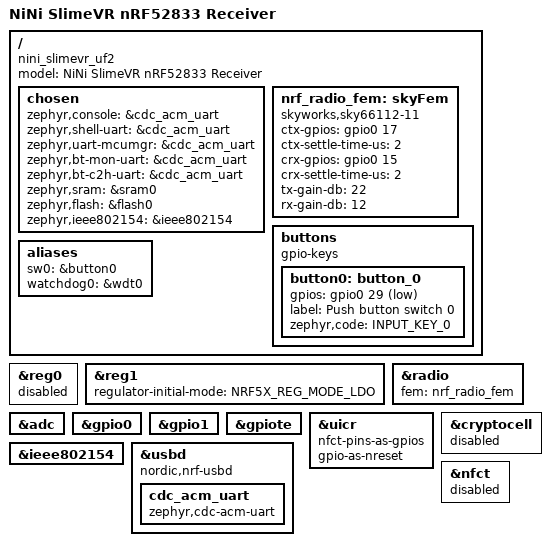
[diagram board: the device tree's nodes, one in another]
// Copyright (c) 2026
// SPDX-License-Identifier: Apache-2.0

/dts-v1/;
#include <nordic/nrf52833_qdaa.dtsi>
#include <zephyr/dt-bindings/input/input-event-codes.h>

/ {
	model = "NiNi SlimeVR nRF52833 Receiver";
	compatible = "nini_slimevr_uf2";

	chosen {
		zephyr,console = &cdc_acm_uart;
		zephyr,shell-uart = &cdc_acm_uart;
		zephyr,uart-mcumgr = &cdc_acm_uart;
		zephyr,bt-mon-uart = &cdc_acm_uart;
		zephyr,bt-c2h-uart = &cdc_acm_uart;
		zephyr,sram = &sram0;
		zephyr,flash = &flash0;
		zephyr,ieee802154 = &ieee802154;
	};

	nrf_radio_fem: skyFem {
		compatible = "skyworks,sky66112-11", "generic-fem-two-ctrl-pins";
		ctx-gpios = <&gpio0 17 GPIO_ACTIVE_HIGH>;
		ctx-settle-time-us = <2>;
		crx-gpios = <&gpio0 15 GPIO_ACTIVE_HIGH>;
		crx-settle-time-us = <2>;
		tx-gain-db = <22>;
		rx-gain-db = <12>;
	};


	buttons {
		compatible = "gpio-keys";
		button0: button_0 {
			gpios = <&gpio0 29 (GPIO_PULL_UP | GPIO_ACTIVE_LOW)>;
			label = "Push button switch 0";
			zephyr,code = <INPUT_KEY_0>;
		};
	};

	aliases {
		sw0 = &button0;
		watchdog0 = &wdt0;
	};
};

&reg0 {
	status = "disabled";
};

&reg1 {
	regulator-initial-mode = <NRF5X_REG_MODE_LDO>;
};

&radio {
	fem = <&nrf_radio_fem>;
};

&adc {
	status = "okay";
};

&gpio0 {
	status = "okay";
};

&gpio1 {
	status = "okay";
};

&gpiote {
	status = "okay";
};

&uicr {
	nfct-pins-as-gpios;
	gpio-as-nreset;
};

&ieee802154 {
	status = "okay";
};

zephyr_udc0: &usbd {
	compatible = "nordic,nrf-usbd";
	status = "okay";
	cdc_acm_uart: cdc_acm_uart {
		compatible = "zephyr,cdc-acm-uart";
	};
};

&cryptocell {
	status = "disabled";
};

&nfct {
	status = "disabled";
};
